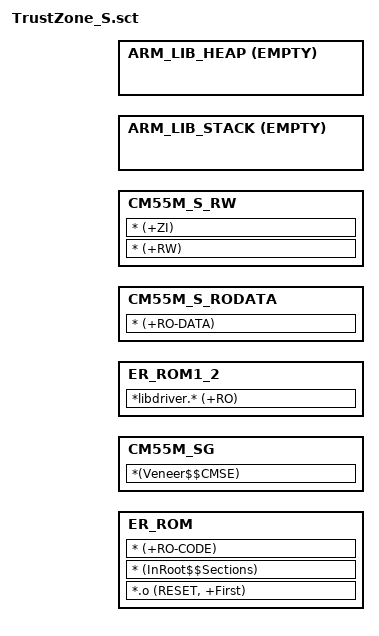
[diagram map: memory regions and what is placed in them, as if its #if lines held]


#include "CM55M_TrustZone_FW_mem.h"

LR_ROM1 CM55M_S_APP_ROM_BASE CM55M_S_APP_ROM_SIZE  {
  ER_ROM +0 {                                     
   *.o (RESET, +First)
   * (InRoot$$Sections)
   * (+RO-CODE)
  }
}

LR_ROM2 CM55M_SG_BASE CM55M_SG_SIZE{  
  CM55M_SG +0 CM55M_SG_SIZE{ 
   *(Veneer$$CMSE)                               
  }
}

#if defined(CM55M_S_APP_ROM2_BASE)
LR_ROM1_2 CM55M_S_APP_ROM2_BASE CM55M_S_APP_ROM2_SIZE  {
  ER_ROM1_2 +0 {                                     
    *libdriver.* (+RO)
  }
}
#endif

LR_ROM3 CM55M_S_APP_DATA_BASE CM55M_S_APP_DATA_SIZE  {
  CM55M_S_RODATA  +0 { 
   * (+RO-DATA)
  }		
  CM55M_S_RW  +0  {
   * (+RW)
   * (+ZI)
  }

  ARM_LIB_STACK __STACK_BASE ALIGN 8 EMPTY -__STACK_S_SIZE {
  }
  
  ARM_LIB_HEAP  __HEAP_BASE ALIGN 8 EMPTY __HEAP_S_SIZE  { 
  }
}

